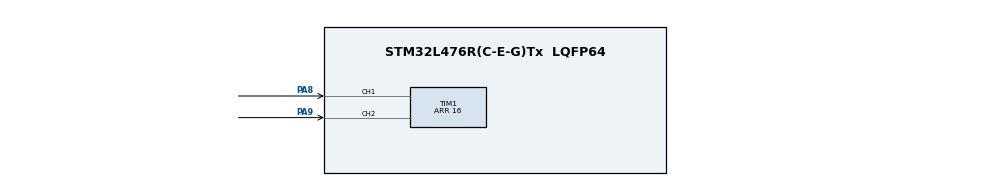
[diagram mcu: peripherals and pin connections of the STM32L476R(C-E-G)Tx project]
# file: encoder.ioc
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Mcu.Family=STM32L4
Mcu.Name=STM32L476R(C-E-G)Tx
Mcu.Package=LQFP64
NVIC.PriorityGroup=NVIC_PRIORITYGROUP_4
PA8.GPIO_ModeDefaultPP=GPIO_MODE_AF_PP
PA8.GPIO_PuPd=GPIO_PULLUP
PA8.Signal=S_TIM1_CH1
PA9.GPIO_PuPd=GPIO_PULLUP
PA9.Signal=S_TIM1_CH2
ProjectManager.HeapSize=0x200
ProjectManager.StackSize=0x400
ProjectManager.TargetToolchain=MDK-ARM V4
RCC.HSE_VALUE=8000000
RCC.HSI_VALUE=16000000
RCC.LSE_VALUE=32768
RCC.MSI_VALUE=4000000
RCC.VCOOutputFreq_Value=32000000
SH.S_TIM1_CH1.0=TIM1_CH1,Encoder_Interface
SH.S_TIM1_CH2.0=TIM1_CH2,Encoder_Interface
TIM1.EncoderMode=TIM_ENCODERMODE_TI12
TIM1.IC1Filter=5
TIM1.Period=16
board=encoder

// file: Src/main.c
/**
  ******************************************************************************
  * @file           : main.c
  * @brief          : Main program body
  ******************************************************************************
  ** This notice applies to any and all portions of this file
  * that are not between comment pairs USER CODE BEGIN and
  * USER CODE END. Other portions of this file, whether
  * inserted by the user or by software development tools
  * are owned by their respective copyright owners.
  *
  * COPYRIGHT(c) 2018 STMicroelectronics
  *
  * Redistribution and use in source and binary forms, with or without modification,
  * are permitted provided that the following conditions are met:
  *   1. Redistributions of source code must retain the above copyright notice,
  *      this list of conditions and the following disclaimer.
  *   2. Redistributions in binary form must reproduce the above copyright notice,
  *      this list of conditions and the following disclaimer in the documentation
  *      and/or other materials provided with the distribution.
  *   3. Neither the name of STMicroelectronics nor the names of its contributors
  *      may be used to endorse or promote products derived from this software
  *      without specific prior written permission.
  *
  * THIS SOFTWARE IS PROVIDED BY THE COPYRIGHT HOLDERS AND CONTRIBUTORS "AS IS"
  * AND ANY EXPRESS OR IMPLIED WARRANTIES, INCLUDING, BUT NOT LIMITED TO, THE
  * IMPLIED WARRANTIES OF MERCHANTABILITY AND FITNESS FOR A PARTICULAR PURPOSE ARE
  * DISCLAIMED. IN NO EVENT SHALL THE COPYRIGHT HOLDER OR CONTRIBUTORS BE LIABLE
  * FOR ANY DIRECT, INDIRECT, INCIDENTAL, SPECIAL, EXEMPLARY, OR CONSEQUENTIAL
  * DAMAGES (INCLUDING, BUT NOT LIMITED TO, PROCUREMENT OF SUBSTITUTE GOODS OR
  * SERVICES; LOSS OF USE, DATA, OR PROFITS; OR BUSINESS INTERRUPTION) HOWEVER
  * CAUSED AND ON ANY THEORY OF LIABILITY, WHETHER IN CONTRACT, STRICT LIABILITY,
  * OR TORT (INCLUDING NEGLIGENCE OR OTHERWISE) ARISING IN ANY WAY OUT OF THE USE
  * OF THIS SOFTWARE, EVEN IF ADVISED OF THE POSSIBILITY OF SUCH DAMAGE.
  *
  ******************************************************************************
  */
#include "main.h"
#include "stm32l4xx_hal.h"

TIM_HandleTypeDef htim1;

/* USER CODE BEGIN PV */
/* Private variables ---------------------------------------------------------*/

/* USER CODE END PV */

void SystemClock_Config(void);
static void MX_GPIO_Init(void);
static void MX_TIM1_Init(void);

/* USER CODE BEGIN PFP */
/* Private function prototypes -----------------------------------------------*/

/* USER CODE END PFP */

int main(void)
{

  /* MCU Configuration----------------------------------------------------------*/

  /* Reset of all peripherals, Initializes the Flash interface and the Systick. */
  HAL_Init();

  /* Configure the system clock */
  SystemClock_Config();

  /* Initialize all configured peripherals */
  MX_GPIO_Init();
  MX_TIM1_Init();
  /* USER CODE BEGIN 2 */
 HAL_TIM_Encoder_Start(&htim1,TIM_CHANNEL_ALL);
  /* USER CODE END 2 */

  /* Infinite loop */
  /* USER CODE BEGIN WHILE */
  while (1)
  {
	i  = TIM1->CNT;
  /* USER CODE END WHILE */

  }

}

void SystemClock_Config(void)
{

  RCC_OscInitTypeDef RCC_OscInitStruct;
  RCC_ClkInitTypeDef RCC_ClkInitStruct;

    /**Initializes the CPU, AHB and APB busses clocks
    */
  RCC_OscInitStruct.OscillatorType = RCC_OSCILLATORTYPE_MSI;
  RCC_OscInitStruct.MSIState = RCC_MSI_ON;
  RCC_OscInitStruct.MSICalibrationValue = 0;
  RCC_OscInitStruct.MSIClockRange = RCC_MSIRANGE_6;
  RCC_OscInitStruct.PLL.PLLState = RCC_PLL_NONE;
  if (HAL_RCC_OscConfig(&RCC_OscInitStruct) != HAL_OK)
  {
    _Error_Handler(__FILE__, __LINE__);
  }

    /**Initializes the CPU, AHB and APB busses clocks
    */
  RCC_ClkInitStruct.ClockType = RCC_CLOCKTYPE_HCLK|RCC_CLOCKTYPE_SYSCLK
                              |RCC_CLOCKTYPE_PCLK1|RCC_CLOCKTYPE_PCLK2;
  RCC_ClkInitStruct.SYSCLKSource = RCC_SYSCLKSOURCE_MSI;
  RCC_ClkInitStruct.AHBCLKDivider = RCC_SYSCLK_DIV1;
  RCC_ClkInitStruct.APB1CLKDivider = RCC_HCLK_DIV1;
  RCC_ClkInitStruct.APB2CLKDivider = RCC_HCLK_DIV1;

  if (HAL_RCC_ClockConfig(&RCC_ClkInitStruct, FLASH_LATENCY_0) != HAL_OK)
  {
    _Error_Handler(__FILE__, __LINE__);
  }

    /**Configure the main internal regulator output voltage
    */
  if (HAL_PWREx_ControlVoltageScaling(PWR_REGULATOR_VOLTAGE_SCALE1) != HAL_OK)
  {
    _Error_Handler(__FILE__, __LINE__);
  }

    /**Configure the Systick interrupt time
    */
  HAL_SYSTICK_Config(HAL_RCC_GetHCLKFreq()/1000);

    /**Configure the Systick
    */
  HAL_SYSTICK_CLKSourceConfig(SYSTICK_CLKSOURCE_HCLK);

  /* SysTick_IRQn interrupt configuration */
  HAL_NVIC_SetPriority(SysTick_IRQn, 0, 0);
}

/* TIM1 init function */
static void MX_TIM1_Init(void)
{

  TIM_Encoder_InitTypeDef sConfig;
  TIM_MasterConfigTypeDef sMasterConfig;

  htim1.Instance = TIM1;
  htim1.Init.Prescaler = 0;
  htim1.Init.CounterMode = TIM_COUNTERMODE_UP;
  htim1.Init.Period = 16;
  htim1.Init.ClockDivision = TIM_CLOCKDIVISION_DIV1;
  htim1.Init.RepetitionCounter = 0;
  htim1.Init.AutoReloadPreload = TIM_AUTORELOAD_PRELOAD_DISABLE;
  sConfig.EncoderMode = TIM_ENCODERMODE_TI12;
  sConfig.IC1Polarity = TIM_ICPOLARITY_RISING;
  sConfig.IC1Selection = TIM_ICSELECTION_DIRECTTI;
  sConfig.IC1Prescaler = TIM_ICPSC_DIV1;
  sConfig.IC1Filter = 5;
  sConfig.IC2Polarity = TIM_ICPOLARITY_RISING;
  sConfig.IC2Selection = TIM_ICSELECTION_DIRECTTI;
  sConfig.IC2Prescaler = TIM_ICPSC_DIV1;
  sConfig.IC2Filter = 0;
  if (HAL_TIM_Encoder_Init(&htim1, &sConfig) != HAL_OK)
  {
    _Error_Handler(__FILE__, __LINE__);
  }

  sMasterConfig.MasterOutputTrigger = TIM_TRGO_RESET;
  sMasterConfig.MasterOutputTrigger2 = TIM_TRGO2_RESET;
  sMasterConfig.MasterSlaveMode = TIM_MASTERSLAVEMODE_DISABLE;
  if (HAL_TIMEx_MasterConfigSynchronization(&htim1, &sMasterConfig) != HAL_OK)
  {
    _Error_Handler(__FILE__, __LINE__);
  }

}

/** Pinout Configuration
*/
static void MX_GPIO_Init(void)
{

  /* GPIO Ports Clock Enable */
  __HAL_RCC_GPIOA_CLK_ENABLE();

}

void _Error_Handler(char *file, int line)
{
  while(1)
  {
  }
}

/************************ (C) COPYRIGHT STMicroelectronics *****END OF FILE****/
